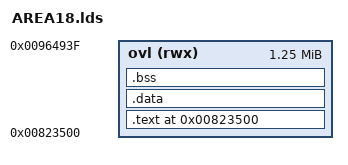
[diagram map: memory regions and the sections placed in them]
/* AREA18.lds -- GNU ld linker script for Extermination overlay AREA18
 * overlay_id=15, load=0x00823500
 * GENERATED by tools/overlay/link_overlay.py -- do not edit by hand.
 */

INPUT(
    "/work/build/overlays/AREA18/filler/_code_merged.o"
    "/work/build/overlays/AREA18/filler/data_section_0.o"
)

MEMORY
{
    ovl (rwx) : ORIGIN = 0x00823500, LENGTH = 0x141440
}

/* ---- Absolute symbols ---- */
D_00275C1C = 0x00275C1C;
D_00275C24 = 0x00275C24;
D_00275C28 = 0x00275C28;
D_00275C2C = 0x00275C2C;
D_overlay_AREA18_00823D80 = 0x00823D80;
func_00000008 = 0x00000008;
func_0000000C = 0x0000000C;


SECTIONS
{
    /* ---- TEXT ---- */
    .text 0x00823500 :
    {
        "/work/build/overlays/AREA18/filler/_code_merged.o" (.text)
        * (.text)
    } > ovl

    /* ---- DATA ---- */
    .data :
    {
        "/work/build/overlays/AREA18/filler/data_section_0.o" (.data)
        * (.data)
        * (.rodata)
        * (.sdata)
    } > ovl

    /* ---- BSS (not written to file) ---- */
    .bss (NOLOAD) :
    {
        __bss_start = .;
        * (.bss)
        * (.sbss)
        * (COMMON)
        __bss_end = .;
    } > ovl

    /* Discard everything else */
    /DISCARD/ : { * (.comment) * (.reginfo) * (.mwcats) * (.ctor) }
}
